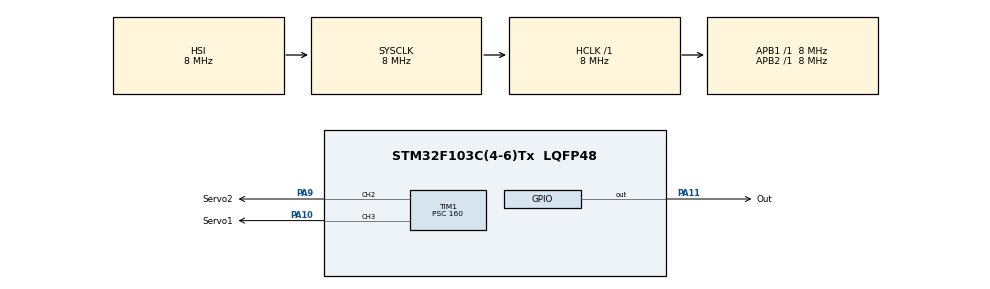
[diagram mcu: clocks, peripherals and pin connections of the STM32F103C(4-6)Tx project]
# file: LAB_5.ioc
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Mcu.Family=STM32F1
Mcu.Name=STM32F103C(4-6)Tx
Mcu.Package=LQFP48
NVIC.PriorityGroup=NVIC_PRIORITYGROUP_4
NVIC.TIM2_IRQn=true\:0\:0\:false\:false\:true\:true\:true
PA10.GPIO_Label=Servo1
PA10.Signal=S_TIM1_CH3
PA11.GPIO_Label=Out
PA11.Signal=GPIO_Output
PA9.GPIO_Label=Servo2
PA9.Signal=S_TIM1_CH2
ProjectManager.HeapSize=0x200
ProjectManager.StackSize=0x400
ProjectManager.TargetToolchain=STM32CubeIDE
RCC.AHBFreq_Value=8000000
RCC.APB1Freq_Value=8000000
RCC.APB1TimFreq_Value=8000000
RCC.APB2Freq_Value=8000000
RCC.APB2TimFreq_Value=8000000
RCC.HCLKFreq_Value=8000000
RCC.SYSCLKFreq_VALUE=8000000
RCC.USBFreq_Value=8000000
SH.S_TIM1_CH2.0=TIM1_CH2,PWM Generation2 CH2
SH.S_TIM1_CH3.0=TIM1_CH3,PWM Generation3 CH3
TIM1.Channel-PWM\ Generation2\ CH2=TIM_CHANNEL_2
TIM1.Channel-PWM\ Generation3\ CH3=TIM_CHANNEL_3
TIM1.OCPolarity_2=TIM_OCPOLARITY_LOW
TIM1.OCPolarity_3=TIM_OCPOLARITY_LOW
TIM1.Period=1000
TIM1.Prescaler=160
TIM1.Pulse-PWM\ Generation2\ CH2=25
TIM1.Pulse-PWM\ Generation3\ CH3=125
TIM2.Period=200
TIM2.Prescaler=800
TIM2.TIM_MasterOutputTrigger=TIM_TRGO_UPDATE
VP_SYS_VS_ND.Mode=No_Debug
VP_TIM1_VS_ClockSourceINT.Mode=Internal
VP_TIM2_VS_ClockSourceINT.Mode=Internal
board=custom

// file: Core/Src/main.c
/* USER CODE BEGIN Header */
/**
  ******************************************************************************
  * @file           : main.c
  * @brief          : Main program body
  ******************************************************************************
  * @attention
  *
  * <h2><center>&copy; Copyright (c) 2021 STMicroelectronics.
  * All rights reserved.</center></h2>
  *
  * This software component is licensed by ST under BSD 3-Clause license,
  * the "License"; You may not use this file except in compliance with the
  * License. You may obtain a copy of the License at:
  *                        opensource.org/licenses/BSD-3-Clause
  *
  ******************************************************************************
  */
/* USER CODE END Header */
#include "main.h"

TIM_HandleTypeDef htim1;
TIM_HandleTypeDef htim2;

/* USER CODE BEGIN PV */
int myPulsePWM1 = 25, myPulsePWM2 = 25;
/* USER CODE END PV */

void SystemClock_Config(void);
static void MX_GPIO_Init(void);
static void MX_TIM1_Init(void);
static void MX_TIM2_Init(void);

int main(void)
{

  /* MCU Configuration--------------------------------------------------------*/

  /* Reset of all peripherals, Initializes the Flash interface and the Systick. */
  HAL_Init();

  /* Configure the system clock */
  SystemClock_Config();

  /* Initialize all configured peripherals */
  MX_GPIO_Init();
  MX_TIM1_Init();
  MX_TIM2_Init();
  /* USER CODE BEGIN 2 */
  HAL_TIM_PWM_Start(&htim1, TIM_CHANNEL_2);
  HAL_TIM_PWM_Start(&htim1, TIM_CHANNEL_3);
  HAL_TIM_PWM_Start(&htim1, TIM_CHANNEL_4);
  HAL_TIM_Base_Start_IT(&htim2);
  /* USER CODE END 2 */

  /* Infinite loop */
  /* USER CODE BEGIN WHILE */
  while (1)
  {
	  HAL_GPIO_TogglePin(Out_GPIO_Port, Out_Pin);
	  HAL_Delay(500);
    /* USER CODE END WHILE */

  }
}

void SystemClock_Config(void)
{
  RCC_OscInitTypeDef RCC_OscInitStruct = {0};
  RCC_ClkInitTypeDef RCC_ClkInitStruct = {0};

  /** Initializes the RCC Oscillators according to the specified parameters
  * in the RCC_OscInitTypeDef structure.
  */
  RCC_OscInitStruct.OscillatorType = RCC_OSCILLATORTYPE_HSI;
  RCC_OscInitStruct.HSIState = RCC_HSI_ON;
  RCC_OscInitStruct.HSICalibrationValue = RCC_HSICALIBRATION_DEFAULT;
  RCC_OscInitStruct.PLL.PLLState = RCC_PLL_NONE;
  if (HAL_RCC_OscConfig(&RCC_OscInitStruct) != HAL_OK)
  {
    Error_Handler();
  }
  /** Initializes the CPU, AHB and APB buses clocks
  */
  RCC_ClkInitStruct.ClockType = RCC_CLOCKTYPE_HCLK|RCC_CLOCKTYPE_SYSCLK
                              |RCC_CLOCKTYPE_PCLK1|RCC_CLOCKTYPE_PCLK2;
  RCC_ClkInitStruct.SYSCLKSource = RCC_SYSCLKSOURCE_HSI;
  RCC_ClkInitStruct.AHBCLKDivider = RCC_SYSCLK_DIV1;
  RCC_ClkInitStruct.APB1CLKDivider = RCC_HCLK_DIV1;
  RCC_ClkInitStruct.APB2CLKDivider = RCC_HCLK_DIV1;

  if (HAL_RCC_ClockConfig(&RCC_ClkInitStruct, FLASH_LATENCY_0) != HAL_OK)
  {
    Error_Handler();
  }
}

static void MX_TIM1_Init(void)
{

  TIM_ClockConfigTypeDef sClockSourceConfig = {0};
  TIM_MasterConfigTypeDef sMasterConfig = {0};
  TIM_OC_InitTypeDef sConfigOC = {0};
  TIM_BreakDeadTimeConfigTypeDef sBreakDeadTimeConfig = {0};

  htim1.Instance = TIM1;
  htim1.Init.Prescaler = 160;
  htim1.Init.CounterMode = TIM_COUNTERMODE_UP;
  htim1.Init.Period = 1000;
  htim1.Init.ClockDivision = TIM_CLOCKDIVISION_DIV1;
  htim1.Init.RepetitionCounter = 0;
  htim1.Init.AutoReloadPreload = TIM_AUTORELOAD_PRELOAD_DISABLE;
  if (HAL_TIM_Base_Init(&htim1) != HAL_OK)
  {
    Error_Handler();
  }
  sClockSourceConfig.ClockSource = TIM_CLOCKSOURCE_INTERNAL;
  if (HAL_TIM_ConfigClockSource(&htim1, &sClockSourceConfig) != HAL_OK)
  {
    Error_Handler();
  }
  if (HAL_TIM_PWM_Init(&htim1) != HAL_OK)
  {
    Error_Handler();
  }
  sMasterConfig.MasterOutputTrigger = TIM_TRGO_RESET;
  sMasterConfig.MasterSlaveMode = TIM_MASTERSLAVEMODE_DISABLE;
  if (HAL_TIMEx_MasterConfigSynchronization(&htim1, &sMasterConfig) != HAL_OK)
  {
    Error_Handler();
  }
  sConfigOC.OCMode = TIM_OCMODE_PWM1;
  sConfigOC.Pulse = 25;
  sConfigOC.OCPolarity = TIM_OCPOLARITY_LOW;
  sConfigOC.OCNPolarity = TIM_OCNPOLARITY_HIGH;
  sConfigOC.OCFastMode = TIM_OCFAST_DISABLE;
  sConfigOC.OCIdleState = TIM_OCIDLESTATE_RESET;
  sConfigOC.OCNIdleState = TIM_OCNIDLESTATE_RESET;
  if (HAL_TIM_PWM_ConfigChannel(&htim1, &sConfigOC, TIM_CHANNEL_2) != HAL_OK)
  {
    Error_Handler();
  }
  sConfigOC.Pulse = 125;
  if (HAL_TIM_PWM_ConfigChannel(&htim1, &sConfigOC, TIM_CHANNEL_3) != HAL_OK)
  {
    Error_Handler();
  }
  sBreakDeadTimeConfig.OffStateRunMode = TIM_OSSR_DISABLE;
  sBreakDeadTimeConfig.OffStateIDLEMode = TIM_OSSI_DISABLE;
  sBreakDeadTimeConfig.LockLevel = TIM_LOCKLEVEL_OFF;
  sBreakDeadTimeConfig.DeadTime = 0;
  sBreakDeadTimeConfig.BreakState = TIM_BREAK_DISABLE;
  sBreakDeadTimeConfig.BreakPolarity = TIM_BREAKPOLARITY_HIGH;
  sBreakDeadTimeConfig.AutomaticOutput = TIM_AUTOMATICOUTPUT_DISABLE;
  if (HAL_TIMEx_ConfigBreakDeadTime(&htim1, &sBreakDeadTimeConfig) != HAL_OK)
  {
    Error_Handler();
  }
  HAL_TIM_MspPostInit(&htim1);

}

static void MX_TIM2_Init(void)
{

  TIM_ClockConfigTypeDef sClockSourceConfig = {0};
  TIM_MasterConfigTypeDef sMasterConfig = {0};

  htim2.Instance = TIM2;
  htim2.Init.Prescaler = 800;
  htim2.Init.CounterMode = TIM_COUNTERMODE_UP;
  htim2.Init.Period = 200;
  htim2.Init.ClockDivision = TIM_CLOCKDIVISION_DIV1;
  htim2.Init.AutoReloadPreload = TIM_AUTORELOAD_PRELOAD_DISABLE;
  if (HAL_TIM_Base_Init(&htim2) != HAL_OK)
  {
    Error_Handler();
  }
  sClockSourceConfig.ClockSource = TIM_CLOCKSOURCE_INTERNAL;
  if (HAL_TIM_ConfigClockSource(&htim2, &sClockSourceConfig) != HAL_OK)
  {
    Error_Handler();
  }
  sMasterConfig.MasterOutputTrigger = TIM_TRGO_UPDATE;
  sMasterConfig.MasterSlaveMode = TIM_MASTERSLAVEMODE_DISABLE;
  if (HAL_TIMEx_MasterConfigSynchronization(&htim2, &sMasterConfig) != HAL_OK)
  {
    Error_Handler();
  }

}

static void MX_GPIO_Init(void)
{
  GPIO_InitTypeDef GPIO_InitStruct = {0};

  /* GPIO Ports Clock Enable */
  __HAL_RCC_GPIOA_CLK_ENABLE();

  /*Configure GPIO pin Output Level */
  HAL_GPIO_WritePin(Out_GPIO_Port, Out_Pin, GPIO_PIN_RESET);

  /*Configure GPIO pin : Out_Pin */
  GPIO_InitStruct.Pin = Out_Pin;
  GPIO_InitStruct.Mode = GPIO_MODE_OUTPUT_PP;
  GPIO_InitStruct.Pull = GPIO_NOPULL;
  GPIO_InitStruct.Speed = GPIO_SPEED_FREQ_LOW;
  HAL_GPIO_Init(Out_GPIO_Port, &GPIO_InitStruct);

}

/* USER CODE BEGIN 4 */
void HAL_TIM_PeriodElapsedCallback(TIM_HandleTypeDef *htim)
{
	if(htim->Instance == TIM2)
	{
		static int status1 = 0, status2 = 0;
		if(!status1)
		{
			myPulsePWM1 -= 1;
		}
		else
		{
			myPulsePWM1 += 1;
		}
		if(!status2)
		{
			myPulsePWM2 += 5;
		}
		else
		{
			myPulsePWM2 -= 5;
		}
		__HAL_TIM_SetCompare(&htim1, TIM_CHANNEL_2, myPulsePWM1);
		__HAL_TIM_SetCompare(&htim1, TIM_CHANNEL_3, myPulsePWM2);
		if(myPulsePWM1 < 25 || myPulsePWM1 > 125)
		{
			status1 ^= 1;
		}
		if(myPulsePWM2 < 25 || myPulsePWM2 > 125)
		{
			status2 ^= 1;
		}
	}
}
/* USER CODE END 4 */

void Error_Handler(void)
{
  __disable_irq();
  while (1)
  {
  }
}

/************************ (C) COPYRIGHT STMicroelectronics *****END OF FILE****/
